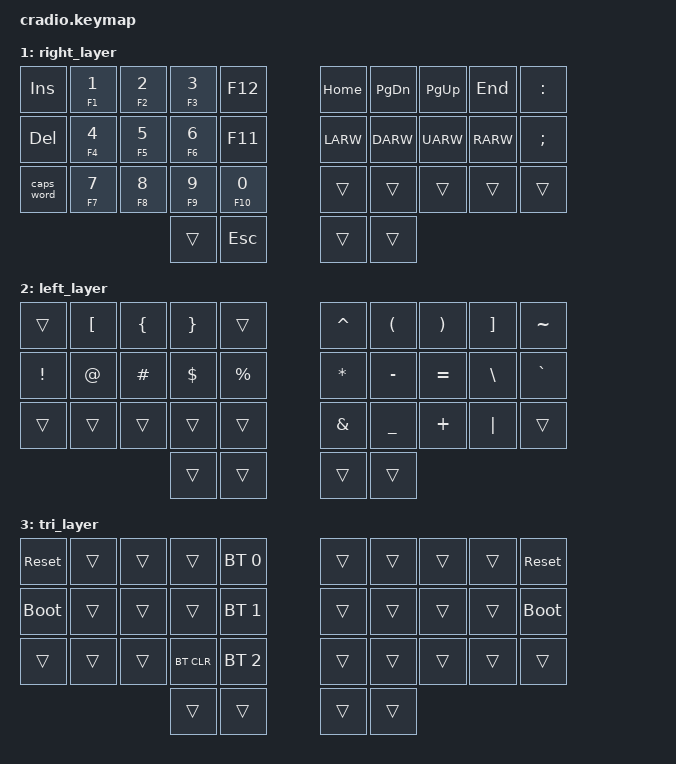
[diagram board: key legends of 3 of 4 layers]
// Copyright (c) 2022 The ZMK Contributors
// SPDX-License-Identifier: MIT

#include <behaviors.dtsi>
#include <dt-bindings/zmk/keys.h>
#include <dt-bindings/zmk/bt.h>

// Home row mods macro
#define HRML(k1,k2,k3,k4) &ht LALT k1  &ht LSHFT k2  &ht LCTRL k3  &ht LGUI k4
#define HRMR(k1,k2,k3,k4) &ht RGUI k1  &ht RCTRL k2  &ht RSHFT k3  &ht RALT k4

/ {
    behaviors {
        ht: hold_tap {
            label = "hold_tap";
            compatible = "zmk,behavior-hold-tap";
            #binding-cells = <2>;
            flavor = "tap-preferred";
            tapping-term-ms = <220>;
            quick-tap-ms = <150>;
            global-quick-tap;
            bindings = <&kp>, <&kp>;
        };
    };

    conditional_layers {
        compatible = "zmk,conditional-layers";
        tri_layer {
            if-layers = <1 2>;
            then-layer = <3>;
        };
    };

    keymap {
        compatible = "zmk,keymap";
        default_layer {
            bindings = <
        //╭──────────┬──────────┬──────────┬──────────┬──────────╮   ╭──────────┬──────────┬──────────┬──────────┬──────────╮
        //│  Q       │  W       │  E       │  R       │  T       │   │  Y       │  U       │  I       │  O       │  P       │
            &kp Q      &kp W      &kp E      &kp R      &kp T          &kp Y      &kp U      &kp I      &kp O      &kp P
        //├──────────┼──────────┼──────────┼──────────┼──────────┤   ├──────────┼──────────┼──────────┼──────────┼──────────┤
        //│  A       │  S       │  D       │  F       │  G       │   │  H       │  J       │  K       │  L       │ ' "      │
            HRML(A,        S,         D,         F)     &kp G          &kp H      HRMR(J,        K,         L,        SQT)
        //├──────────┼──────────┼──────────┼──────────┼──────────┤   ├──────────┼──────────┼──────────┼──────────┼──────────┤
        //│  Z       │  X       │  C       │  V       │  B       │   │  N       │  M       │ , <      │ . >      │ / ?      │
            &kp Z      &kp X      &kp C      &kp V      &kp B          &kp N      &kp M      &kp COMMA  &kp DOT    &kp FSLH
        //╰──────────┴──────────┴──────────┼──────────┼──────────┤   ├──────────┼──────────┼──────────┴──────────┴──────────╯
                                            &lt 2 TAB   &kp SPACE      &kp ENTER &lt 1 BSPC
        //                                 ╰──────────┴──────────╯   ╰──────────┴──────────╯
            >;
        };

        right_layer {
            bindings = <
        //╭──────────┬──────────┬──────────┬──────────┬──────────╮   ╭──────────┬──────────┬──────────┬──────────┬──────────╮
        //│ INSERT   │  1       │  2       │  3       │          │   │ HOME     │ PAGE DN  │ PAGE UP  │ END      │  :       │
            &kp INS   &mt F1 N1  &mt F2 N2  &mt F3 N3   &kp F12        &kp HOME   &kp PG_DN  &kp PG_UP  &kp END    &kp COLON
        //├──────────┼──────────┼──────────┼──────────┼──────────┤   ├──────────┼──────────┼──────────┼──────────┼──────────┤
        //│ DELETE   │  4       │  5       │  6       │          │   │ LEFT     │ DOWN     │ UP       │ RIGHT    │  ;       │
            &kp DEL   &mt F4 N4  &mt F5 N5  &mt F6 N6   &kp F11        &kp LARW   &kp DARW   &kp UARW   &kp RARW   &kp SEMI
        //├──────────┼──────────┼──────────┼──────────┼──────────┤   ├──────────┼──────────┼──────────┼──────────┼──────────┤
        //│ CAPS     │  7       │  8       │  9       │  0       │   │          │          │          │          │          │
           &caps_word &mt F7 N7  &mt F8 N8  &mt F9 N9  &mt F10 N0       &trans     &trans     &trans     &trans     &trans
        //╰──────────┴──────────┴──────────┼──────────┼──────────┤   ├──────────┼──────────┼──────────┴──────────┴──────────╯
                                             &trans     &kp ESC        &trans     &trans
        //                                 ╰──────────┴──────────╯   ╰──────────┴──────────╯
            >;
        };

        left_layer {
            bindings = <
        //╭──────────┬──────────┬──────────┬──────────┬──────────╮   ╭──────────┬──────────┬──────────┬──────────┬──────────╮
        //│          │  [       │  {       │  }       │          │   │  ^       │  (       │  )       │  ]       │  ~       │
            &trans     &kp LBKT   &kp LBRC   &kp RBRC   &trans         &kp CARET  &kp LPAR   &kp RPAR   &kp RBKT   &kp TILDE
        //├──────────┼──────────┼──────────┼──────────┼──────────┤   ├──────────┼──────────┼──────────┼──────────┼──────────┤
        //│  !       │  @       │  #       │  $       │  %       │   │  *       │  -       │  =       │  \       │  `       │
            &kp EXCL   &kp AT     &kp HASH   &kp DLLR   &kp PRCNT      &kp ASTRK  &kp MINUS  &kp EQUAL  &kp BSLH   &kp GRAVE
        //├──────────┼──────────┼──────────┼──────────┼──────────┤   ├──────────┼──────────┼──────────┼──────────┼──────────┤
        //│          │          │          │          │          │   │  &       │  _       │  +       │  │       │          │
            &trans     &trans     &trans     &trans     &trans         &kp AMPS   &kp UNDER  &kp PLUS   &kp PIPE   &trans
        //╰──────────┴──────────┴──────────┼──────────┼──────────┤   ├──────────┼──────────┼──────────┴──────────┴──────────╯
                                             &trans     &trans         &trans     &trans
        //                                 ╰──────────┴──────────╯   ╰──────────┴──────────╯
            >;
        };

        tri_layer {
            bindings = <
        //╭──────────┬──────────┬──────────┬──────────┬──────────╮   ╭──────────┬──────────┬──────────┬──────────┬──────────╮
        //│ RESET    │          │          │          │PROFILE 0 │   │          │          │          │          │  RESET   │
            &sys_reset &trans     &trans     &trans    &bt BT_SEL 0    &trans     &trans     &trans     &trans    &sys_reset
        //├──────────┼──────────┼──────────┼──────────┼──────────┤   ├──────────┼──────────┼──────────┼──────────┼──────────┤
        //│BOOTLOADER│          │          │          │PROFILE 1 │   │          │          │          │          │BOOTLOADER│
          &bootloader  &trans     &trans     &trans    &bt BT_SEL 1    &trans     &trans     &trans     &trans    &bootloader
        //├──────────┼──────────┼──────────┼──────────┼──────────┤   ├──────────┼──────────┼──────────┼──────────┼──────────┤
        //│          │          │          │ CLEAR BT │PROFILE 2 │   │          │          │          │          │          │
            &trans     &trans     &trans    &bt BT_CLR &bt BT_SEL 2    &trans     &trans     &trans     &trans     &trans
        //╰──────────┴──────────┴──────────┼──────────┼──────────┤   ├──────────┼──────────┼──────────┴──────────┴──────────╯
                                             &trans     &trans         &trans     &trans
        //                                 ╰──────────┴──────────╯   ╰──────────┴──────────╯
            >;
        };
    };
};
